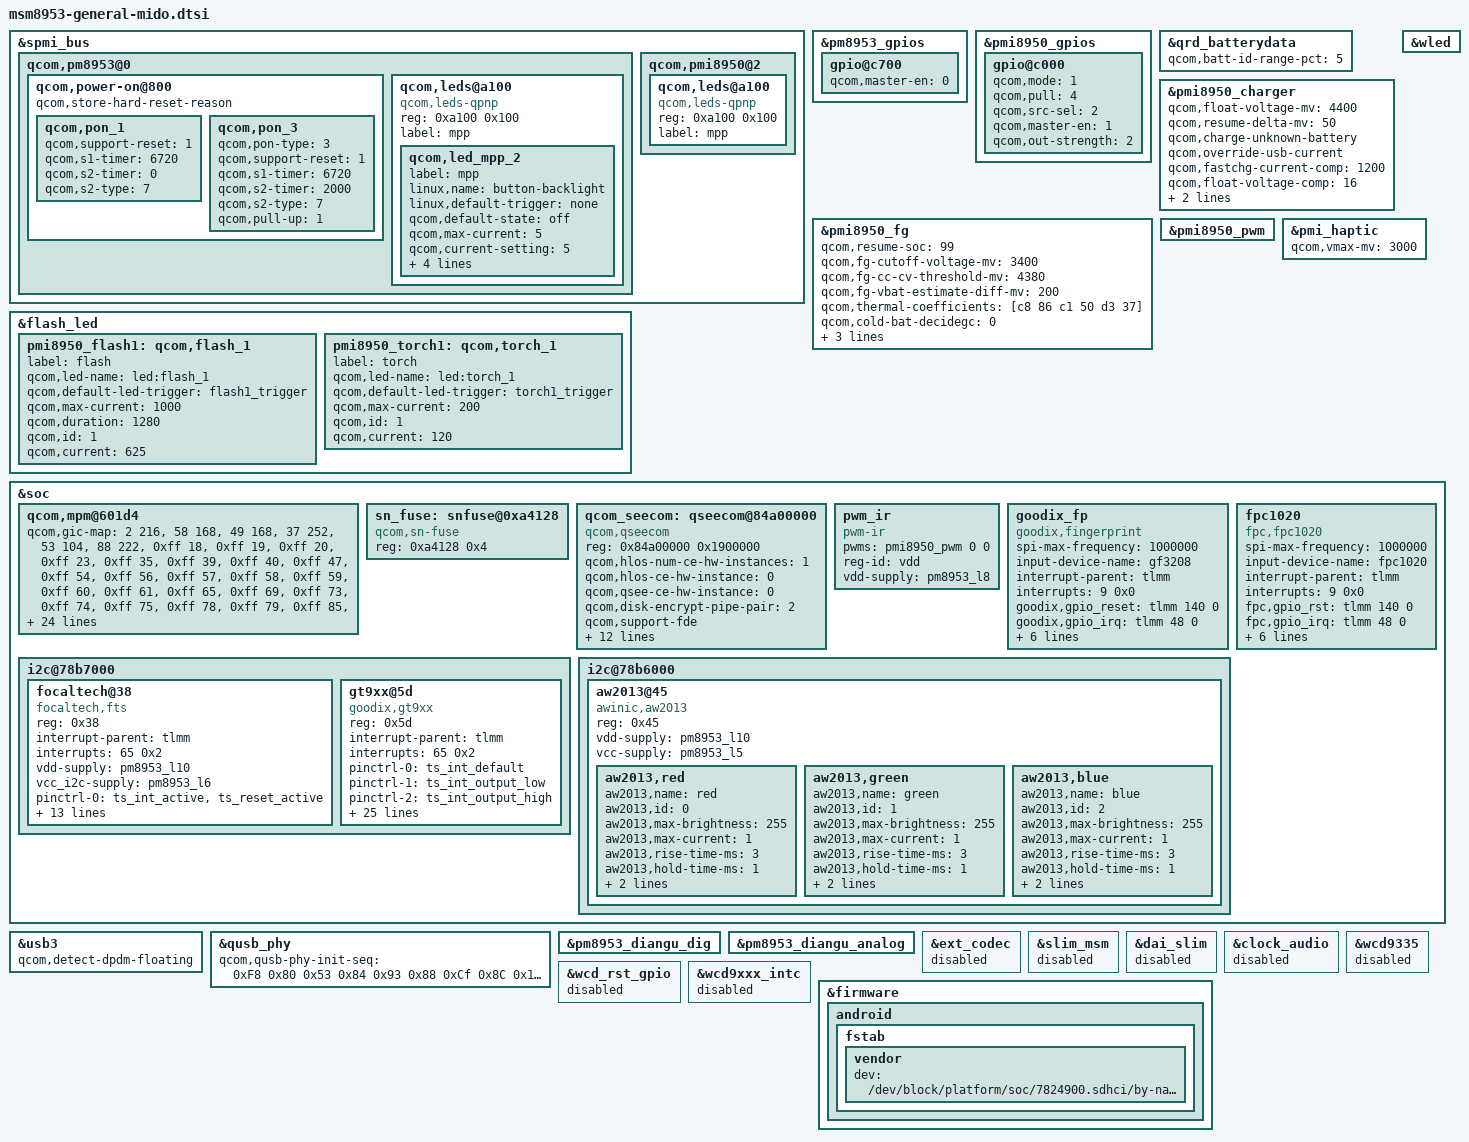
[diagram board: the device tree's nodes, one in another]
/* Copyright (c) 2017, The Linux Foundation. All rights reserved.
 *
 * This program is free software; you can redistribute it and/or modify
 * it under the terms of the GNU General Public License version 2 and
 * only version 2 as published by the Free Software Foundation.
 *
 * This program is distributed in the hope that it will be useful,
 * but WITHOUT ANY WARRANTY; without even the implied warranty of
 * MERCHANTABILITY or FITNESS FOR A PARTICULAR PURPOSE.  See the
 * GNU General Public License for more details.
 */

&spmi_bus {
	qcom,pm8953@0 {
		qcom,power-on@800 {
                       qcom,store-hard-reset-reason;
			qcom,pon_1 {
				qcom,support-reset = <1>;
				qcom,s1-timer = <6720>;
				qcom,s2-timer = <0>;
				qcom,s2-type = <7>;
			};
			qcom,pon_3 {
				qcom,pon-type = <3>;
				qcom,support-reset = <1>;
				qcom,s1-timer = <6720>;
				qcom,s2-timer = <2000>;
				qcom,s2-type = <7>;
				qcom,pull-up = <1>;
			};
		};
                qcom,leds@a100 {
                        status = "okay";
                        compatible = "qcom,leds-qpnp";
                        reg = <0xa100 0x100>;
                        label = "mpp";
                        qcom,led_mpp_2 {
                                label = "mpp";
                                linux,name = "button-backlight";
                                linux,default-trigger = "none";
                                qcom,default-state = "off";
                                qcom,max-current = <5>;
                                qcom,current-setting = <5>;
                                qcom,id = <6>;
                                qcom,mode = "manual";
                                qcom,source-sel = <1>;
                                qcom,mode-ctrl = <0x61>;
                        };
                };
		/delete-node/ qcom,pm8953_typec@bf00;
	};

	qcom,pmi8950@2 {
		qcom,leds@a100 {
			compatible = "qcom,leds-qpnp";
			reg = <0xa100 0x100>;
			label = "mpp";
			/delete-node/ qcom,led_mpp_2;
		};
	};
};

&pm8953_gpios {
	gpio@c700 {
		status = "ok";
		qcom,master-en = <0>;
	};
};

&pmi8950_gpios {
	gpio@c000 {
		qcom,mode = <1>;
		qcom,pull = <4>;
		qcom,src-sel = <2>;
		qcom,master-en = <1>;
		qcom,out-strength = <2>;
		status = "okay";
	};
};

&qrd_batterydata {
	qcom,batt-id-range-pct = <5>;
	#include "batterydata-qrd-sunwoda-4v4-4100mah.dtsi"
	#include "batterydata-qrd-sunwoda-ATL-4v4-4100mah.dtsi"
	#include "batterydata-qrd-coslight-4v4-4100mah.dtsi"
	#include "batterydata-qrd-desay-lisheng-4v4-4100mah.dtsi"
	#include "batterydata-qrd-desay-4v4-4100mah.dtsi"
	/delete-node/ qcom,qrd_msm8937_sku1_2920mah;

};


&pmi8950_charger {
	qcom,float-voltage-mv = <4400>;
	qcom,resume-delta-mv = <50>;
	qcom,charge-unknown-battery;
	qcom,override-usb-current;
	qcom,fastchg-current-comp = <1200>;
	qcom,float-voltage-comp = <16>;
	qcom,thermal-mitigation = <3000 2500 2000 2000 1000 500 0>;
	/delete-property/ qcom,parallel-usb-min-current-ma;
	/delete-property/ qcom,parallel-usb-9v-min-current-ma;
	/delete-property/ qcom,parallel-allowed-lowering-ma;
	/delete-property/ qcom,chg-led-sw-controls;
	/delete-property/ qcom,chg-led-support;
	/delete-property/ qcom,external-typec;
	/delete-property/ qcom,typec-psy-name;
	/delete-property/ qcom,autoadjust-vfloat;
};

&pmi8950_fg {
	qcom,resume-soc = <99>;
	qcom,fg-cutoff-voltage-mv = <3400>;
	qcom,fg-cc-cv-threshold-mv = <4380>;
	qcom,fg-vbat-estimate-diff-mv = <200>;
	qcom,thermal-coefficients = [c8 86 c1 50 d3 37];
	qcom,cold-bat-decidegc = <0>;
	qcom,cool-bat-decidegc = <150>;
	qcom,warm-bat-decidegc = <450>;
	qcom,fg-restore-batt-info;

};

&pmi8950_pwm {
	status = "okay";
};

&wled {
	/delete-property/ qcom,en-ext-pfet-sc-pro;
};

&flash_led {
	pmi8950_flash1: qcom,flash_1 {
		label = "flash";
		qcom,led-name = "led:flash_1";
		qcom,default-led-trigger = "flash1_trigger";
		qcom,max-current = <1000>;
		qcom,duration = <1280>;
		qcom,id = <1>;
		qcom,current = <625>;
	};
	
	pmi8950_torch1: qcom,torch_1 {
		label = "torch";
		qcom,led-name = "led:torch_1";
		qcom,default-led-trigger = "torch1_trigger";
		qcom,max-current = <200>;
		qcom,id = <1>;
		qcom,current = <120>;
	};
};

&pmi_haptic {
	qcom,vmax-mv = <3000>;
};

&soc {
	qcom,mpm@601d4 {
		qcom,gic-map = <2 216>, /* tsens_upper_lower_int */
			<58 168>,   /* qusb2phy_dmse_hv -> hs_phy_irq*/
			<49 168>,   /* qusb2phy_dpse_hv -> hs_phy_irq*/
			<37 252>,   /* qmp_usb3_lfps_rxterm_irq -> ss_phy_irq */
			<53 104>, /* mdss_irq */
			<88 222>, /* ee0_krait_hlos_spmi_periph_irq */
			<0xff 18>,  /* APC_qgicQTmrSecPhysIrptReq */
			<0xff 19>,  /* APC_qgicQTmrNonSecPhysIrptReq */
			<0xff 20>,  /* qgicQTmrVirtIrptReq */
			<0xff 23>,  /* apss_hm */
			<0xff 35>,  /* WDT_barkInt */
			<0xff 39>,  /* arch_mem_timer */
			<0xff 40>,  /* qtmr_phy_irq[0] */
			<0xff 47>,  /* rbif_irq[0] */
			<0xff 54>,  /* gladiator-error */
			<0xff 56>,  /* q6_wdog_expired_irq */
			<0xff 57>,  /* mss_to_apps_irq(0) */
			<0xff 58>,  /* mss_to_apps_irq(1) */
			<0xff 59>,  /* mss_to_apps_irq(2) */
			<0xff 60>,  /* mss_to_apps_irq(3) */
			<0xff 61>,  /* mss_a2_bam_irq */
			<0xff 65>,  /* o_gc_sys_irq[0] */
			<0xff 69>,  /* vbif_irpt */
			<0xff 73>,  /* app_tcu_gbl_flt_irpt_ns */
			<0xff 74>,  /* smmu_bus_intr[2] */
			<0xff 75>,  /* smmu_bus_intr[3] */
			<0xff 78>,  /* smmu_bus_intr[5] */
			<0xff 79>,  /* smmu_bus_intr[6] */
			<0xff 85>,  /* smmu_bus_intr[31] */
			<0xff 86>,  /* smmu_bus_intr[32] */
			<0xff 90>,  /* smmu_bus_intr[33] */
			<0xff 92>,  /* smmu_bus_intr[34] */
			<0xff 93>,  /* smmu_bus_intr[35] */
			<0xff 97>,  /* smmu_bus_intr[10] */
			<0xff 102>, /* smmu_bus_intr[14] */
			<0xff 108>, /* smmu_bus_intr[36] */
			<0xff 109>, /* smmu_bus_intr[37] */
			<0xff 112>, /* smmu_bus_intr[38] */
			<0xff 114>, /* qdsd_intr_out */
			<0xff 126>, /* app_tcu_cxt_irpt_vec[11] */
			<0xff 128>, /* blsp1_peripheral_irq[3] */
			<0xff 131>, /* qup_irq */
			<0xff 136>, /* app_tcu_cxt_irpt_vec[15] */
			<0xff 137>, /* app_tcu_cxt_irpt_vec[16] */
			<0xff 138>, /* app_tcu_cxt_irpt_vec[17] */
			<0xff 139>, /* uart_dm_intr */
			<0xff 140>, /* uart_dm_intr */
			<0xff 141>, /* app_tcu_cxt_irpt_vec[18] */
			<0xff 142>, /* smmu_bus_intr[47] */
			<0xff 143>, /* smmu_bus_intr[48] */
			<0xff 144>, /* smmu_bus_intr[49] */
			<0xff 145>, /* smmu_bus_intr[50] */
			<0xff 146>, /* smmu_bus_intr[51] */
			<0xff 147>, /* smmu_bus_intr[52] */
			<0xff 148>, /* smmu_bus_intr[53] */
			<0xff 149>, /* smmu_bus_intr[54] */
			<0xff 150>, /* smmu_bus_intr[55] */
			<0xff 151>, /* smmu_bus_intr[56] */
			<0xff 152>, /* smmu_bus_intr[57] */
			<0xff 153>, /* smmu_bus_intr[58] */
			<0xff 155>, /* sdc1_irq(0) */
			<0xff 157>, /* sdc2_irq(0) */
			<0xff 166>, /* usb30_pwr_evnt_irq */
			<0xff 167>, /* usb30_bam_irq[0] */
			<0xff 170>, /* sdc1_pwr_cmd_irq */
			<0xff 172>, /* usb30_ctrl_irq[0] */
			<0xff 173>, /* o_wcss_apss_smd_hi */
			<0xff 174>, /* o_wcss_apss_smd_med */
			<0xff 175>, /* o_wcss_apss_smd_low */
			<0xff 176>, /* o_wcss_apss_smsm_irq */
			<0xff 177>, /* o_wcss_apss_wlan_data_xfer_done */
			<0xff 178>, /* o_wcss_apss_wlan_rx_data_avail */
			<0xff 179>, /* o_wcss_apss_asic_intr */
			<0xff 181>, /* o_wcss_apss_wdog_bite_and_reset_rdy */
			<0xff 188>, /* lpass_irq_out_apcs(0) */
			<0xff 189>, /* lpass_irq_out_apcs(1) */
			<0xff 190>, /* lpass_irq_out_apcs(2) */
			<0xff 191>, /* lpass_irq_out_apcs(3) */
			<0xff 192>, /* lpass_irq_out_apcs(4) */
			<0xff 193>, /* lpass_irq_out_apcs(5) */
			<0xff 194>, /* lpass_irq_out_apcs(6) */
			<0xff 195>, /* lpass_irq_out_apcs(7) */
			<0xff 196>, /* lpass_irq_out_apcs(8) */
			<0xff 197>, /* lpass_irq_out_apcs(9) */
			<0xff 198>, /* coresight-tmc-etr interrupt */
			<0xff 200>, /* rpm_ipc(4) */
			<0xff 201>, /* rpm_ipc(5) */
			<0xff 202>, /* rpm_ipc(6) */
			<0xff 203>, /* rpm_ipc(7) */
			<0xff 204>, /* rpm_ipc(24) */
			<0xff 205>, /* rpm_ipc(25) */
			<0xff 206>, /* rpm_ipc(26) */
			<0xff 207>, /* rpm_ipc(27) */
			<0xff 212>, /* lpass_slimbus_bam_ee1_irq */
			<0xff 215>, /* o_bimc_intr[0] */
			<0xff 224>, /* spdm_realtime_irq[1] */
			<0xff 231>, /* arm-smmu global fault */
			<0xff 239>, /* crypto_bam_irq[1]*/
			<0xff 240>, /* summary_irq_kpss */
			<0xff 253>, /* sdc2_pwr_cmd_irq */
			<0xff 257>, /* osmmu_Cirpt[0] */
			<0xff 260>, /* ipa_irq[0] */
			<0xff 262>, /* ipa_bam_irq[0] */
			<0xff 263>, /* ipa_bam_irq[2] */
			<0xff 264>, /* arm-smmu context fault */
			<0xff 269>, /* rpm_wdog_expired_irq */
			<0xff 270>, /* blsp1_bam_irq[0] */
			<0xff 271>, /* blsp1_bam_irq[0] */ /* added by xiaomi */
			<0xff 273>, /* smmu_bus_intr[18] */
			<0xff 274>, /* smmu_bus_intr[19] */
			<0xff 275>, /* rpm_ipc(30) */
			<0xff 276>, /* rpm_ipc(31) */
			<0xff 285>, /* app_tcu_cxt_irpt_vec[0] */
			<0xff 286>, /* app_tcu_cxt_irpt_vec[1] */
			<0xff 287>, /* app_tcu_cxt_irpt_vec[2] */
			<0xff 305>, /* L2_EXTERRIRQ_C0 */
			<0xff 306>, /* L2_EXTERRIRQ_C1 */
			<0xff 307>, /* L2_INTERRIRQ_C0 */
			<0xff 308>, /* L2_INTERRIRQ_C1 */
			<0xff 314>, /* CCISAW_svicInt */
			<0xff 321>, /* q6ss_irq_out(4) */
			<0xff 322>, /* q6ss_irq_out(5) */
			<0xff 323>, /* q6ss_irq_out(6) */
			<0xff 325>, /* q6ss_wdog_exp_irq */
			<0xff 344>, /* sdcc_ice_nonsec_level_irq */
			<0xff 346>; /* tsens_critical_int */
		};
	sn_fuse: snfuse@0xa4128 {
		compatible = "qcom,sn-fuse";
		reg = <0xa4128 0x4>;
		reg-names = "sn-base";
	};

	qcom_seecom: qseecom@84a00000 { /* renamed from caf qseecom@85b00000 */
                compatible = "qcom,qseecom";
                reg = <0x84a00000 0x1900000>; /* changed by xiaomi */
                reg-names = "secapp-region";
                qcom,hlos-num-ce-hw-instances = <1>;
                qcom,hlos-ce-hw-instance = <0>;
                qcom,qsee-ce-hw-instance = <0>;
                qcom,disk-encrypt-pipe-pair = <2>;
                qcom,support-fde;
                qcom,msm-bus,name = "qseecom-noc";
                qcom,msm-bus,num-cases = <4>;
                qcom,msm-bus,num-paths = <1>;
                qcom,support-bus-scaling;
                qcom,msm-bus,vectors-KBps =
                        <55 512 0 0>,
                        <55 512 0 0>,
                        <55 512 120000 1200000>,
                        <55 512 393600 3936000>;
                clocks = <&clock_gcc clk_crypto_clk_src>,
                         <&clock_gcc clk_gcc_crypto_clk>,
                         <&clock_gcc clk_gcc_crypto_ahb_clk>,
                         <&clock_gcc clk_gcc_crypto_axi_clk>;
                clock-names = "core_clk_src", "core_clk",
                                "iface_clk", "bus_clk";
                qcom,ce-opp-freq = <100000000>;
        };

        /delete-node/ qseecom@85b00000;

	pwm_ir {
                compatible = "pwm-ir";
                pwms = <&pmi8950_pwm 0 0>;
                reg-id = "vdd";
                vdd-supply = <&pm8953_l8>;
        };

        goodix_fp {
			compatible = "goodix,fingerprint";
			spi-max-frequency = <1000000>;
			input-device-name = "gf3208";
			interrupt-parent = <&tlmm>;
			interrupts = <9 0x0>;

			goodix,gpio_reset    = <&tlmm 140 0>;
			goodix,gpio_irq      = <&tlmm 48 0>;

			clock-names = "iface_clk", "core_clk";
			clocks = <&clock_gcc clk_gcc_blsp1_ahb_clk>,
			<&clock_gcc clk_gcc_blsp1_qup1_spi_apps_clk>;

			pinctrl-names = "goodixfp_spi_active",
				"goodixfp_reset_reset",
				"goodixfp_reset_active",
				"goodixfp_irq_active";

			pinctrl-0 = <&goodix_spi_active>;
			pinctrl-1 = <&goodix_reset_reset>;
			pinctrl-2 = <&goodix_reset_active>;
			pinctrl-3 = <&goodix_irq_active>;
		};

	fpc1020 {
                compatible = "fpc,fpc1020";
                spi-max-frequency = <1000000>;
                input-device-name = "fpc1020";
                interrupt-parent = <&tlmm>;
                interrupts = <9 0x0>;

                fpc,gpio_rst    = <&tlmm 140 0>;
                fpc,gpio_irq      = <&tlmm 48 0>;

                clock-names = "iface_clk", "core_clk";
                clocks = <&clock_gcc clk_gcc_blsp1_ahb_clk>,
                <&clock_gcc clk_gcc_blsp1_qup1_spi_apps_clk>;

                pinctrl-names = "fpc1020_spi_active",
                        "fpc1020_reset_reset",
                        "fpc1020_reset_active",
                        "fpc1020_irq_active";

                pinctrl-0 = <&fpc_spi_active>;
                pinctrl-1 = <&fpc_reset_reset>;
                pinctrl-2 = <&fpc_reset_active>;
                pinctrl-3 = <&fpc_irq_active>;
        };

	i2c@78b7000 {
                focaltech@38 {
                        compatible = "focaltech,fts";
                        reg = <0x38>;
                        interrupt-parent = <&tlmm>;
                        interrupts = <65 0x2>;
                        vdd-supply = <&pm8953_l10>;
                        vcc_i2c-supply = <&pm8953_l6>;
                        /* pins used by touchscreen */
                        pinctrl-names = "pmx_ts_active","pmx_ts_suspend",
                                                        "pmx_ts_release";
                        pinctrl-0 = <&ts_int_active &ts_reset_active>;
                        pinctrl-1 = <&ts_int_suspend &ts_reset_suspend>;
                        pinctrl-2 = <&ts_release>;
                        focaltech,reset-gpio = <&tlmm 64 0x0>;
                        focaltech,irq-gpio = <&tlmm 65 0x2008>;
                        focaltech,display-coords = <0 0 1080 1920>;
                        focaltech,panel-coords = <0 0 1080 1920>;
                        focaltech,max-touch-number = <10>;
						focaltech,wakeup-gestures-en;
                        focaltech,have-key;
                        focaltech,key-number = <3>;
						focaltech,keys = <172 139 158>;
						focaltech,key-y-coord = <2040>;
						focaltech,key-x-coords = <500 200 800>;
                };

		gt9xx@5d {
			compatible = "goodix,gt9xx";
			reg = <0x5d>;
			status = "okay";
			interrupt-parent = <&tlmm>;
			interrupts = <65 0x2>;
			pinctrl-names = "default", "int-output-low","int-output-high", "int-input";
			pinctrl-0 = <&ts_int_default>;
			pinctrl-1 = <&ts_int_output_low>;
			pinctrl-2 = <&ts_int_output_high>;
			pinctrl-3 = <&ts_int_input>;
			reset-gpios = <&tlmm 64 0x0>;
			irq-gpios = <&tlmm 65 0x2008>;
			irq-flags = <1>;
			vdd_ana-supply = <&pm8953_l10>;
			vcc_i2c-supply = <&pm8953_l6>;
			touchscreen-max-id = <11>;
			touchscreen-size-x = <1080>;
			touchscreen-size-y = <2280>;
			touchscreen-max-w = <512>;
			touchscreen-max-p = <512>;
			goodix,slide-wakeup = <1>;
			goodix,type-a-report = <0>;
			goodix,driver-send-cfg = <1>;
			goodix,resume-in-workqueue = <0>;
			goodix,int-sync = <1>;
			goodix,swap-x2y = <0>;
			goodix,esd-protect = <1>;
			goodix,auto-update-cfg = <1>;
			goodix,auto-update = <1>;
			goodix,power-off-sleep = <0>;
			goodix,pen-suppress-finger = <0>;
			goodix,charger-cmd = <1>;
			goodix,cfg-group0 = [52 38 04 E8 08 0A 7C 10 21
								2A 32 0D 5A 46 1E 55 00 00
								60 22 22 22 04 30 00 00 2E
								87 27 EE 46 48 F1 08 F1 08
								00 C2 33 91 0A 00 00 00 00
								83 50 0C 0F 5A 02 2D 50 84
								E0 A5 19 28 23 04 A2 2F 00
								91 35 00 88 3C 00 80 42 00
								78 4A 00 77 00 00 00 00 00
								00 00 00 00 00 00 00 00 00
								00 00 00 00 00 02 00 04 60
								28 00 00 00 00 00 01 46 00
								00 00 00 32 16 17 0A 0B 0C
								0D 0E 0F 10 11 12 13 14 15
								18 19 1A 1B 00 01 02 03 04
								05 06 07 08 09 FF FF 08 06
								05 04 0A 0C 0E 1E 1F 20 22
								24 29 2A FF FF FF 00 00 00
								00 00 00 00 00 00 2D 28 37
								0A 1E 32 00 0A 00 44 66 32
								0A 4A 84 5B 00 00 00 00 00
								00 2A 5A 00 00 00 00 00 32
								0C 28 00 55 00 40 88 20 8C
								47 33 36 0A 6F 66 1C 00 14
								14 0C 02 44 44 58 9A 4C 83
								85 DF 01];
		};

        };

	i2c@78b6000 { /* BLSP1 QUP3 */
                aw2013@45 {
                        compatible = "awinic,aw2013";
                        reg = <0x45>;
                        vdd-supply = <&pm8953_l10>;
                        vcc-supply = <&pm8953_l5>;

                        aw2013,red {
                                aw2013,name = "red";
                                aw2013,id = <0>;
                                aw2013,max-brightness = <255>;
                                aw2013,max-current = <1>;
                                aw2013,rise-time-ms = <3>;
                                aw2013,hold-time-ms = <1>;
                                aw2013,fall-time-ms = <3>;
                                aw2013,off-time-ms = <3>;
                        };

                        aw2013,green {
                                aw2013,name = "green";
                                aw2013,id = <1>;
                                aw2013,max-brightness = <255>;
                                aw2013,max-current = <1>;
                                aw2013,rise-time-ms = <3>;
                                aw2013,hold-time-ms = <1>;
                                aw2013,fall-time-ms = <3>;
                                aw2013,off-time-ms = <3>;
                        };

                        aw2013,blue {
                                aw2013,name = "blue";
                                aw2013,id = <2>;
                                aw2013,max-brightness = <255>;
                                aw2013,max-current = <1>;
                                aw2013,rise-time-ms = <3>;
                                aw2013,hold-time-ms = <1>;
                                aw2013,fall-time-ms = <3>;
                                aw2013,off-time-ms = <3>;
                        };
                };
        };
};

&usb3 {
	qcom,detect-dpdm-floating;
};

&qusb_phy {
	qcom,qusb-phy-init-seq = <0xF8 0x80
					0x53 0x84 /* changed by xiaomi */
					0x93 0x88 /* changed by xiaomi */
					0xCf 0x8C /* changed by xiaomi */
					0x14 0x9C
					0x30 0x08
					0x79 0x0C
					0x21 0x10
					0x00 0x90
					0x9F 0x1C
					0x00 0x18>;
};


&pm8953_diangu_dig {
	status = "ok";
};

&pm8953_diangu_analog {
	status = "ok";
};

&ext_codec {
	status = "disabled";
};

&slim_msm {
	status = "disabled";
};

&dai_slim {
	status = "disabled";
};

&clock_audio {
	status = "disabled";
};

&wcd9335 {
	status = "disabled";
};

&wcd_rst_gpio {
	status = "disabled";
};

&wcd9xxx_intc {
	status = "disabled";
};

&firmware {
	android {
		fstab {
			vendor {
				dev = "/dev/block/platform/soc/7824900.sdhci/by-name/cust";
			};
		};
	};
};
